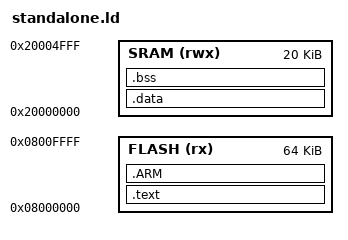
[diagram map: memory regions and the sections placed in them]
/* Entry Point */
ENTRY(Reset_Handler)

MEMORY
{
    FLASH (rx) : ORIGIN = 0x08000000, LENGTH = 64K
    SRAM (rwx) : ORIGIN = 0x20000000, LENGTH = 20K
}

SECTIONS
{
    .text :
    {
        KEEP(*(.isr_vector))
        *(.text*)
        *(.rodata*)
        *(.eh_frame)
	    _etext = .;
    } > FLASH

    .ARM :  AT (ADDR(.text) + SIZEOF(.text))
    {
        __exidx_start = .;
        *(.ARM.exidx*)
        __exidx_end = .;
    } >FLASH

    /* used by the startup to initialize data */
    _sidata = .;

    .data : AT ( _sidata )
    {
      . = ALIGN(4);
      _sdata = .;        /* create a global symbol at data start */
      *(.data)           /* .data sections */
      *(.data*)          /* .data* sections */
      . = ALIGN(4);
      _edata = .;        /* define a global symbol at data end */
    } >SRAM

    .bss :
    {
        _sbss = .;
        *(.bss*)
        *(COMMON)
        _ebss = .;
    } > SRAM
}
